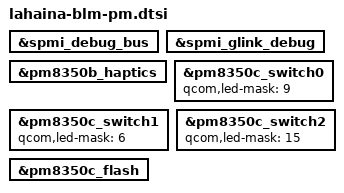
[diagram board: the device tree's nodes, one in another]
#include "../lahaina-blm_common/lahaina-blm_common-pm.dtsi"

&spmi_debug_bus {
    status = "ok";
};

&spmi_glink_debug {
    status = "ok";
};

&pm8350b_haptics {
    status = "ok";
};

&pm8350c_switch0 {
    qcom,led-mask = <9>; /* Channels 1 & 4 */
};

&pm8350c_switch1 {
    qcom,led-mask = <6>; /* Channels 2 & 3 */
};

&pm8350c_switch2 {
    qcom,led-mask = <15>; /* All Channels */
};

&pm8350c_flash {
    status = "ok";
};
